# NVMNW register map
Vendor: Texas Instruments
Peripheral module from a debugger description file (folder CC26x4).
Registers are 32-bit, read-write, reset 0xFFFFFFFF unless marked. A register's access mark holds for its fields unless they carry their own. Offsets are as the file gives them; lines under a group give offsets from that group; [hi:lo] are bit positions; {n}, {i} and the like mark numbered series; 'fields as' and 'values as' point back to an identical list; <NAME> marks a mode.

## NVMNW
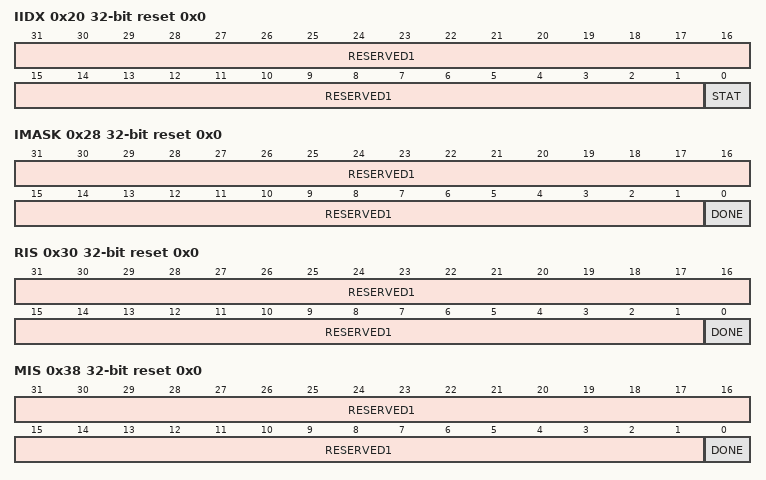
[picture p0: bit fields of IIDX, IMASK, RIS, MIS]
0x20 IIDX ro reset 0x0 — Internal. Only to be used through TI provided API.
  [31:1] RESERVED1 — Internal. Only to be used through TI provided API.
  [0] STAT — Internal. Only to be used through TI provided API.
    1=DONE (Internal. Only to be used through TI provided API.); 0=NO_INTR (Internal. Only to be used through TI provided API.)
0x28 IMASK access per field reset 0x0 — Internal. Only to be used through TI provided API.
  [31:1] RESERVED1 ro — Internal. Only to be used through TI provided API.
  [0] DONE rw — Internal. Only to be used through TI provided API.
    1=ENABLED (Internal. Only to be used through TI provided API.); 0=DISABLED (Internal. Only to be used through TI provided API.)
0x30 RIS ro reset 0x0 — Internal. Only to be used through TI provided API.
  [31:1] RESERVED1 — Internal. Only to be used through TI provided API.
  [0] DONE — Internal. Only to be used through TI provided API.
    1=SET (Internal. Only to be used through TI provided API.); 0=CLR (Internal. Only to be used through TI provided API.)
0x38 MIS ro reset 0x0 — Internal. Only to be used through TI provided API.
  fields as RIS
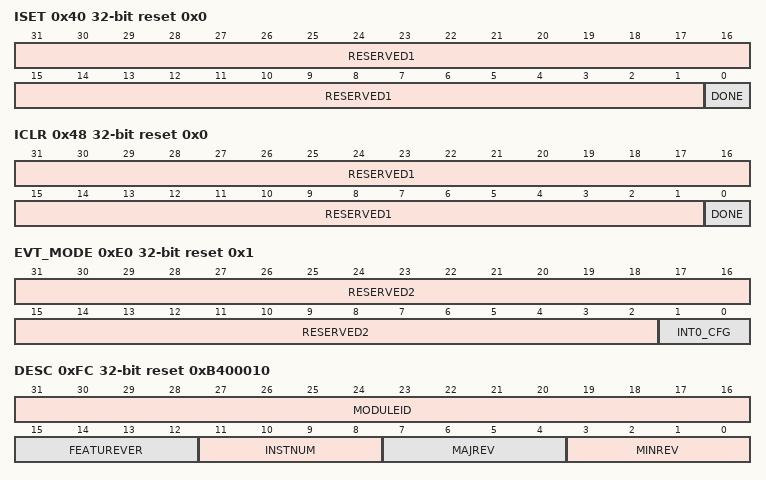
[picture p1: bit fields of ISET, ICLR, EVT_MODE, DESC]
0x40 ISET access per field reset 0x0 — Internal. Only to be used through TI provided API.
  [31:1] RESERVED1 ro — Internal. Only to be used through TI provided API.
  [0] DONE wo — Internal. Only to be used through TI provided API.
    1=SET (Internal. Only to be used through TI provided API.); 0=NO_EFFECT (Internal. Only to be used through TI provided API.)
0x48 ICLR access per field reset 0x0 — Internal. Only to be used through TI provided API.
  [31:1] RESERVED1 ro — Internal. Only to be used through TI provided API.
  [0] DONE wo — Internal. Only to be used through TI provided API.
    1=CLR (Internal. Only to be used through TI provided API.); 0=NO_EFFECT (Internal. Only to be used through TI provided API.)
0xE0 EVT_MODE ro reset 0x1 — Internal. Only to be used through TI provided API.
  [31:2] RESERVED2 — Internal. Only to be used through TI provided API.
  [1:0] INT0_CFG — Internal. Only to be used through TI provided API.
    2=HARDWARE (Internal. Only to be used through TI provided API.); 1=SOFTWARE (Internal. Only to be used through TI provided API.); 0=DISABLE (Internal. Only to be used through TI provided API.)
0xFC DESC ro reset 0xB400010 — Internal. Only to be used through TI provided API.
  [31:16] MODULEID — Internal. Only to be used through TI provided API.
    0xFFFF=MAXIMUM (Internal. Only to be used through TI provided API.); 0=MINIMUM (Internal. Only to be used through TI provided API.)
  [15:12] FEATUREVER — Internal. Only to be used through TI provided API.
    15=MAXIMUM (Internal. Only to be used through TI provided API.); 0=MINIMUM (Internal. Only to be used through TI provided API.)
  [11:8] INSTNUM — Internal. Only to be used through TI provided API.
    values as FEATUREVER
  [7:4] MAJREV — Internal. Only to be used through TI provided API.
    values as FEATUREVER
  [3:0] MINREV — Internal. Only to be used through TI provided API.
    values as FEATUREVER
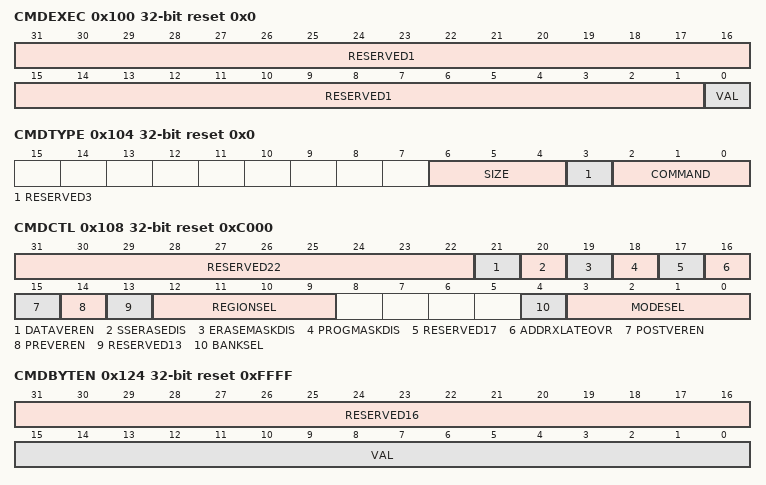
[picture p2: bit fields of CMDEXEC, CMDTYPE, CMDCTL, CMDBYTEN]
0x100 CMDEXEC access per field reset 0x0 — Internal. Only to be used through TI provided API.
  [31:1] RESERVED1 ro — Internal. Only to be used through TI provided API.
  [0] VAL rw — Internal. Only to be used through TI provided API.
    1=EXECUTE (Internal. Only to be used through TI provided API.); 0=NOEXECUTE (Internal. Only to be used through TI provided API.)
0x104 CMDTYPE access per field reset 0x0 — Internal. Only to be used through TI provided API.
  [6:4] SIZE rw — Internal. Only to be used through TI provided API.
    5=BANK (Internal. Only to be used through TI provided API.); 4=SECTOR (Internal. Only to be used through TI provided API.); 3=EIGHTWORD (Internal. Only to be used through TI provided API.); 2=FOURWORD (Internal. Only to be used through TI provided API.); 1=TWOWORD (Internal. Only to be used through TI provided API.); 0=ONEWORD (Internal. Only to be used through TI provided API.)
  [3] RESERVED3 ro — Internal. Only to be used through TI provided API.
  [2:0] COMMAND rw — Internal. Only to be used through TI provided API.
    6=BLANKVERIFY (Internal. Only to be used through TI provided API.); 5=CLEARSTATUS (Internal. Only to be used through TI provided API.); 4=MODECHANGE (Internal. Only to be used through TI provided API.); 3=READVERIFY (Internal. Only to be used through TI provided API.); 2=ERASE (Internal. Only to be used through TI provided API.); 1=PROGRAM (Internal. Only to be used through TI provided API.); 0=NOOP (Internal. Only to be used through TI provided API.)
0x108 CMDCTL access per field reset 0xC000 — Internal. Only to be used through TI provided API.
  [31:22] RESERVED22 ro — Internal. Only to be used through TI provided API.
  [21] DATAVEREN rw — Internal. Only to be used through TI provided API.
    1=ENABLE (Internal. Only to be used through TI provided API.); 0=DISABLE (Internal. Only to be used through TI provided API.)
  [20] SSERASEDIS rw — Internal. Only to be used through TI provided API.
    1=DISABLE (Internal. Only to be used through TI provided API.); 0=ENABLE (Internal. Only to be used through TI provided API.)
  [19] ERASEMASKDIS rw — Internal. Only to be used through TI provided API.
    values as SSERASEDIS
  [18] PROGMASKDIS rw — Internal. Only to be used through TI provided API.
    values as SSERASEDIS
  [17] RESERVED17 ro — Internal. Only to be used through TI provided API.
  [16] ADDRXLATEOVR rw — Internal. Only to be used through TI provided API.
    1=OVERRIDE (Internal. Only to be used through TI provided API.); 0=NOOVERRIDE (Internal. Only to be used through TI provided API.)
  [15] POSTVEREN rw — Internal. Only to be used through TI provided API.
    values as DATAVEREN
  [14] PREVEREN rw — Internal. Only to be used through TI provided API.
    values as DATAVEREN
  [13] RESERVED13 ro — Internal. Only to be used through TI provided API.
  [12:9] REGIONSEL rw — Internal. Only to be used through TI provided API.
    8=ENGR (Internal. Only to be used through TI provided API.); 4=TRIM (Internal. Only to be used through TI provided API.); 2=NONMAIN (Internal. Only to be used through TI provided API.); 1=MAIN (Internal. Only to be used through TI provided API.)
  [4] BANKSEL rw — Internal. Only to be used through TI provided API.
  [3:0] MODESEL rw — Internal. Only to be used through TI provided API.
    15=ERASEBNK (Internal. Only to be used through TI provided API.); 14=PGMMW (Internal. Only to be used through TI provided API.); 12=ERASESECT (Internal. Only to be used through TI provided API.); 11=ERASEVER (Internal. Only to be used through TI provided API.); 10=PGMSW (Internal. Only to be used through TI provided API.); 9=PGMVER (Internal. Only to be used through TI provided API.); 7=RDMARG1B (Internal. Only to be used through TI provided API.); 6=RDMARG0B (Internal. Only to be used through TI provided API.); 4=RDMARG1 (Internal. Only to be used through TI provided API.); 2=RDMARG0 (Internal. Only to be used through TI provided API.); 0=READ (Internal. Only to be used through TI provided API.)
0x120 CMDADDR reset 0x0 — Internal. Only to be used through TI provided API.
  [31:0] VAL
    0xFFFFFFFF=MAXIMUM (Internal. Only to be used through TI provided API.); 0=MINIMUM (Internal. Only to be used through TI provided API.)
0x124 CMDBYTEN access per field reset 0xFFFF — Internal. Only to be used through TI provided API.
  [31:16] RESERVED16 ro — Internal. Only to be used through TI provided API.
  [15:0] VAL rw — Internal. Only to be used through TI provided API.
    values as DESC.MODULEID
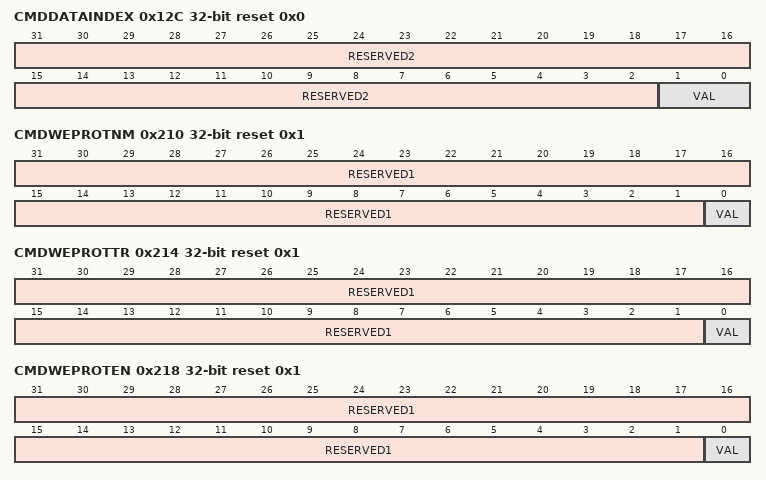
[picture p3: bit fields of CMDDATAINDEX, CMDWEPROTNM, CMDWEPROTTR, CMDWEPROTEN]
0x12C CMDDATAINDEX access per field reset 0x0 — Internal. Only to be used through TI provided API.
  [31:2] RESERVED2 ro — Internal. Only to be used through TI provided API.
  [1:0] VAL rw — Internal. Only to be used through TI provided API.
    3=MAXIMUM (Internal. Only to be used through TI provided API.); 0=MINIMUM (Internal. Only to be used through TI provided API.)
{0x130+4i} CMDDATA{i} (i=0..15) — Internal. Only to be used through TI provided API.
  fields as CMDADDR
0x1D0 CMDWEPROTA — Internal. Only to be used through TI provided API.
  fields as CMDADDR
0x1D4 CMDWEPROTB — Internal. Only to be used through TI provided API.
  fields as CMDADDR
0x210 CMDWEPROTNM access per field reset 0x1 — Internal. Only to be used through TI provided API.
  [31:1] RESERVED1 ro — Internal. Only to be used through TI provided API.
  [0] VAL rw — Internal. Only to be used through TI provided API.
    1=MAXIMUM (Internal. Only to be used through TI provided API.); 0=MINIMUM (Internal. Only to be used through TI provided API.)
0x214 CMDWEPROTTR access per field reset 0x1 — Internal. Only to be used through TI provided API.
  fields as CMDWEPROTNM
0x218 CMDWEPROTEN access per field reset 0x1 — Internal. Only to be used through TI provided API.
  fields as CMDWEPROTNM
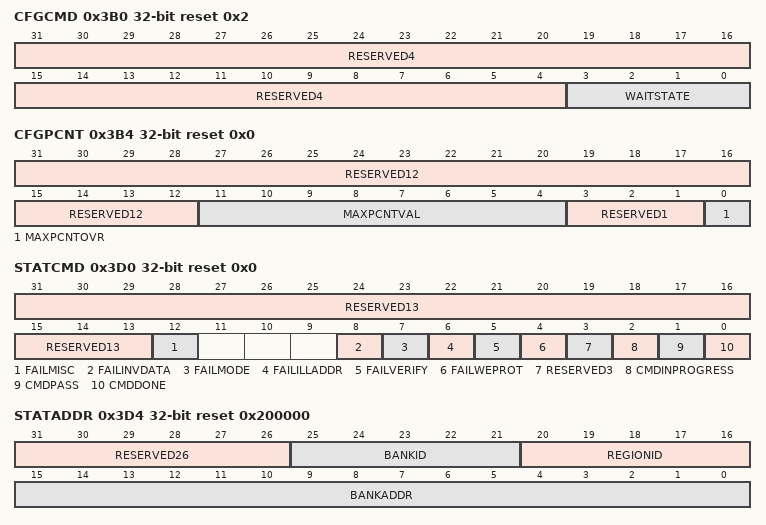
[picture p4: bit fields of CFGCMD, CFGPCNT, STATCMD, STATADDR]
0x3B0 CFGCMD access per field reset 0x2 — Internal. Only to be used through TI provided API.
  [31:4] RESERVED4 ro — Internal. Only to be used through TI provided API.
  [3:0] WAITSTATE rw — Internal. Only to be used through TI provided API.
    values as DESC.FEATUREVER
0x3B4 CFGPCNT access per field reset 0x0 — Internal. Only to be used through TI provided API.
  [31:12] RESERVED12 ro — Internal. Only to be used through TI provided API.
  [11:4] MAXPCNTVAL rw — Internal. Only to be used through TI provided API.
    255=MAXIMUM (Internal. Only to be used through TI provided API.); 0=MINIMUM (Internal. Only to be used through TI provided API.)
  [3:1] RESERVED1 ro — Internal. Only to be used through TI provided API.
  [0] MAXPCNTOVR rw — Internal. Only to be used through TI provided API.
    1=OVERRIDE (Internal. Only to be used through TI provided API.); 0=DEFAULT (Internal. Only to be used through TI provided API.)
0x3D0 STATCMD ro reset 0x0 — Internal. Only to be used through TI provided API.
  [31:13] RESERVED13 — Internal. Only to be used through TI provided API.
  [12] FAILMISC — Internal. Only to be used through TI provided API.
    1=STATFAIL (Internal. Only to be used through TI provided API.); 0=STATNOFAIL (Internal. Only to be used through TI provided API.)
  [8] FAILINVDATA — Internal. Only to be used through TI provided API.
    values as FAILMISC
  [7] FAILMODE — Internal. Only to be used through TI provided API.
    values as FAILMISC
  [6] FAILILLADDR — Internal. Only to be used through TI provided API.
    values as FAILMISC
  [5] FAILVERIFY — Internal. Only to be used through TI provided API.
    values as FAILMISC
  [4] FAILWEPROT — Internal. Only to be used through TI provided API.
    values as FAILMISC
  [3] RESERVED3 — Internal. Only to be used through TI provided API.
  [2] CMDINPROGRESS — Internal. Only to be used through TI provided API.
    1=STATINPROGRESS (Internal. Only to be used through TI provided API.); 0=STATCOMPLETE (Internal. Only to be used through TI provided API.)
  [1] CMDPASS — Internal. Only to be used through TI provided API.
    1=STATPASS (Internal. Only to be used through TI provided API.); 0=STATFAIL (Internal. Only to be used through TI provided API.)
  [0] CMDDONE — Internal. Only to be used through TI provided API.
    1=STATDONE (Internal. Only to be used through TI provided API.); 0=STATNOTDONE (Internal. Only to be used through TI provided API.)
0x3D4 STATADDR ro reset 0x200000 — Internal. Only to be used through TI provided API.
  [31:26] RESERVED26 — Internal. Only to be used through TI provided API.
  [25:21] BANKID — Internal. Only to be used through TI provided API.
    16=BANK4 (Internal. Only to be used through TI provided API.); 8=BANK3 (Internal. Only to be used through TI provided API.); 4=BANK2 (Internal. Only to be used through TI provided API.); 2=BANK1 (Internal. Only to be used through TI provided API.); 1=BANK0 (Internal. Only to be used through TI provided API.)
  [20:16] REGIONID — Internal. Only to be used through TI provided API.
    values as CMDCTL.REGIONSEL
  [15:0] BANKADDR — Internal. Only to be used through TI provided API.
    values as DESC.MODULEID
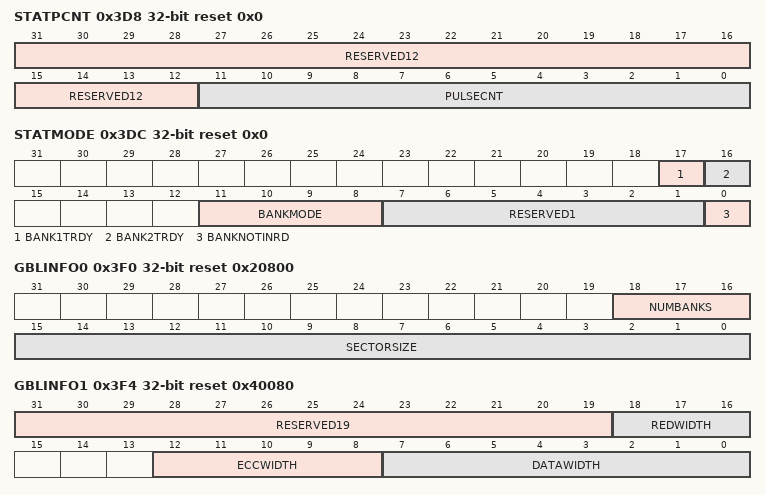
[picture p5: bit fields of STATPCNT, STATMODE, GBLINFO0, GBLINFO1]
0x3D8 STATPCNT ro reset 0x0 — Internal. Only to be used through TI provided API.
  [31:12] RESERVED12 — Internal. Only to be used through TI provided API.
  [11:0] PULSECNT — Internal. Only to be used through TI provided API.
    0xFFF=MAXIMUM (Internal. Only to be used through TI provided API.); 0=MINIMUM (Internal. Only to be used through TI provided API.)
0x3DC STATMODE ro reset 0x0 — Internal. Only to be used through TI provided API.
  [17] BANK1TRDY — Internal. Only to be used through TI provided API.
    1=TRUE (Internal. Only to be used through TI provided API.); 0=FALSE (Internal. Only to be used through TI provided API.)
  [16] BANK2TRDY — Internal. Only to be used through TI provided API.
    values as BANK1TRDY
  [11:8] BANKMODE — Internal. Only to be used through TI provided API.
    values as CMDCTL.MODESEL
  [7:1] RESERVED1 — Internal. Only to be used through TI provided API.
  [0] BANKNOTINRD — Internal. Only to be used through TI provided API.
0x3F0 GBLINFO0 ro reset 0x20800 — Internal. Only to be used through TI provided API.
  [18:16] NUMBANKS — Internal. Only to be used through TI provided API.
    5=MAXIMUM (Internal. Only to be used through TI provided API.); 1=MINIMUM (Internal. Only to be used through TI provided API.)
  [15:0] SECTORSIZE — Internal. Only to be used through TI provided API.
    0x800=TWOKB (Internal. Only to be used through TI provided API.); 0x400=ONEKB (Internal. Only to be used through TI provided API.)
0x3F4 GBLINFO1 ro reset 0x40080 — Internal. Only to be used through TI provided API.
  [31:19] RESERVED19 — Internal. Only to be used through TI provided API.
  [18:16] REDWIDTH — Internal. Only to be used through TI provided API.
    4=W4BIT (Internal. Only to be used through TI provided API.); 2=W2BIT (Internal. Only to be used through TI provided API.); 0=W0BIT (Internal. Only to be used through TI provided API.)
  [12:8] ECCWIDTH — Internal. Only to be used through TI provided API.
    16=W16BIT (Internal. Only to be used through TI provided API.); 8=W8BIT (Internal. Only to be used through TI provided API.); 0=W0BIT (Internal. Only to be used through TI provided API.)
  [7:0] DATAWIDTH — Internal. Only to be used through TI provided API.
    128=W128BIT (Internal. Only to be used through TI provided API.); 64=W64BIT (Internal. Only to be used through TI provided API.)
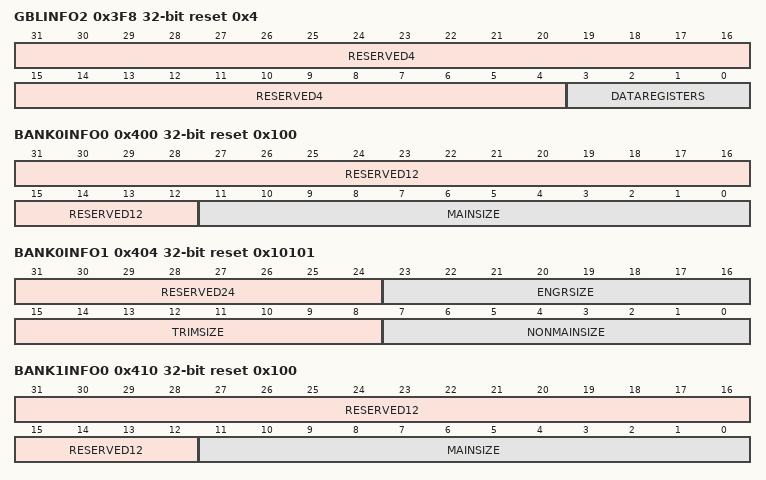
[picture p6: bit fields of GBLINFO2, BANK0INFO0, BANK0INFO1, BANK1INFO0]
0x3F8 GBLINFO2 ro reset 0x4 — Internal. Only to be used through TI provided API.
  [31:4] RESERVED4 — Internal. Only to be used through TI provided API.
  [3:0] DATAREGISTERS — Internal. Only to be used through TI provided API.
    8=MAXIMUM (Internal. Only to be used through TI provided API.); 1=MINIMUM (Internal. Only to be used through TI provided API.)
0x400 BANK0INFO0 ro reset 0x100 — Internal. Only to be used through TI provided API.
  [31:12] RESERVED12 — Internal. Only to be used through TI provided API.
  [11:0] MAINSIZE — Internal. Only to be used through TI provided API.
    0x200=MAXSECTORS (Internal. Only to be used through TI provided API.); 8=MINSECTORS (Internal. Only to be used through TI provided API.)
0x404 BANK0INFO1 ro reset 0x10101 — Internal. Only to be used through TI provided API.
  [31:24] RESERVED24 — Internal. Only to be used through TI provided API.
  [23:16] ENGRSIZE — Internal. Only to be used through TI provided API.
    32=MAXSECTORS (Internal. Only to be used through TI provided API.); 0=MINSECTORS (Internal. Only to be used through TI provided API.)
  [15:8] TRIMSIZE — Internal. Only to be used through TI provided API.
    values as ENGRSIZE
  [7:0] NONMAINSIZE — Internal. Only to be used through TI provided API.
    values as ENGRSIZE
0x410 BANK1INFO0 ro reset 0x100 — Internal. Only to be used through TI provided API.
  fields as BANK0INFO0
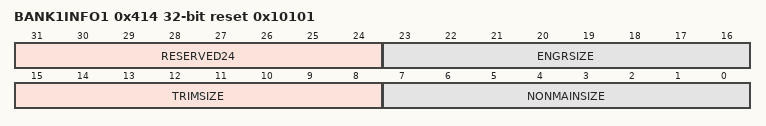
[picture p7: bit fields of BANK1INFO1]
0x414 BANK1INFO1 ro reset 0x10101 — Internal. Only to be used through TI provided API.
  fields as BANK0INFO1
